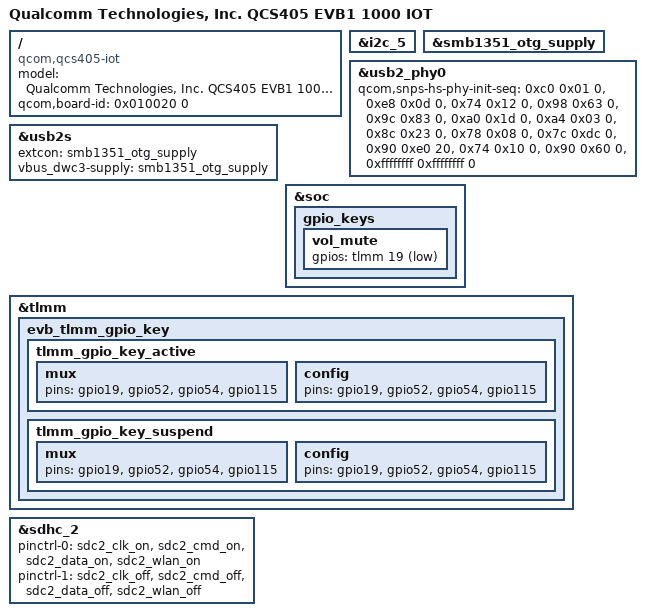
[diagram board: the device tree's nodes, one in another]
/*
 * Copyright (c) 2018-2019, The Linux Foundation. All rights reserved.
 *
 * This program is free software; you can redistribute it and/or modify
 * it under the terms of the GNU General Public License version 2 and
 * only version 2 as published by the Free Software Foundation.
 *
 * This program is distributed in the hope that it will be useful,
 * but WITHOUT ANY WARRANTY; without even the implied warranty of
 * MERCHANTABILITY or FITNESS FOR A PARTICULAR PURPOSE.  See the
 * GNU General Public License for more details.
 */

/dts-v1/;

#include "qcs405.dtsi"
#include "qcs405-wsa-audio-overlay.dtsi"
#include "qcs405-circular-pca9956.dtsi"

/ {
	model = "Qualcomm Technologies, Inc. QCS405 EVB1 1000 IOT";
	compatible = "qcom,qcs405-iot", "qcom,qcs405", "qcom,iot";
	qcom,board-id = <0x010020 0>;
};

&i2c_5 {
	status = "ok";
};

&smb1351_otg_supply {
	status = "ok";
};

&usb2_phy0 {
	qcom,snps-hs-phy-init-seq =
		<0xc0 0x01 0>,
		<0xe8 0x0d 0>,
		<0x74 0x12 0>,
		<0x98 0x63 0>,
		<0x9c 0x83 0>,
		<0xa0 0x1d 0>,
		<0xa4 0x03 0>,
		<0x8c 0x23 0>,
		<0x78 0x08 0>,
		<0x7c 0xdc 0>,
		<0x90 0xe0 20>,
		<0x74 0x10 0>,
		<0x90 0x60 0>,
		<0xffffffff 0xffffffff 0>;
};

&usb2s {
	extcon = <&smb1351_otg_supply>;
	vbus_dwc3-supply = <&smb1351_otg_supply>;
};

&soc {
	gpio_keys {
		vol_mute {
			gpios = <&tlmm 19 GPIO_ACTIVE_LOW>;
		};
	};
};

&tlmm {
	evb_tlmm_gpio_key{
		tlmm_gpio_key_active: tlmm_gpio_key_active {
			mux {
				pins = "gpio19","gpio52","gpio54","gpio115";
			};

			config {
				pins = "gpio19","gpio52","gpio54","gpio115";
			};
		};

		tlmm_gpio_key_suspend: tlmm_gpio_key_suspend {
			mux {
				pins = "gpio19","gpio52","gpio54","gpio115";
			};

			config {
				pins = "gpio19","gpio52","gpio54","gpio115";
			};
		};
	};
};

&sdhc_2 {
	/delete-property/ qcom,nonhotplug;

	pinctrl-0 = <&sdc2_clk_on &sdc2_cmd_on &sdc2_data_on
			&sdc2_wlan_on>;
	pinctrl-1 = <&sdc2_clk_off &sdc2_cmd_off &sdc2_data_off
			&sdc2_wlan_off>;
};
